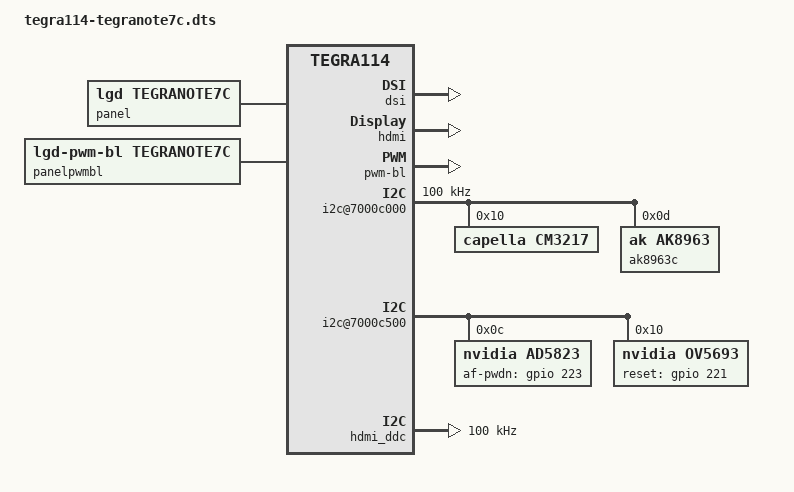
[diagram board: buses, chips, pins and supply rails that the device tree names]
/*
 * Copyright (c) 2013-2014, NVIDIA CORPORATION.  All rights reserved.
 *
 * This program is free software; you can redistribute it and/or modify it
 * under the terms and conditions of the GNU General Public License,
 * version 2, as published by the Free Software Foundation.
 *
 * This program is distributed in the hope it will be useful, but WITHOUT
 * ANY WARRANTY; without even the implied warranty of MERCHANTABILITY or
 * FITNESS FOR A PARTICULAR PURPOSE.  See the GNU General Public License for
 * more details.
 *
 * You should have received a copy of the GNU General Public License
 * along with this program.  If not, see <http://www.gnu.org/licenses/>.
 */

/dts-v1/;

/include/ "tegra114-tegranote7c-common.dtsi"

/ {
	host1x {
		/* tegradc.0 */
		dc@54200000 {
			status = "okay";
			nvidia,dc-flags = "dc_flag_en";
			nvidia,emc-clk-rate = <204000000>;
			nvidia,cmu-enable = <0>;
			dc-default-out {
				nvidia,out-type = "dsi";
				nvidia,out-width = <94>;
				nvidia,out-height = <150>;
				nvidia,out-flags = "continuous_initialized";
				nvidia,out-parent-clk = "pll_d_out0";
			};
			display-timings {
				800x1200-32 {
					clock-frequency = <70666000>;
					hactive = <800>;
					vactive = <1280>;
					hfront-porch = <32>;
					hback-porch = <57>;
					hsync-len = <1>;
					vfront-porch = <28>;
					vback-porch = <14>;
					vsync-len = <1>;
					nvidia,h-ref-to-sync = <10>;
					nvidia,v-ref-to-sync = <1>;
				};
			};
			framebuffer-data {
				nvidia,fb-bpp = <32>; /* bits per pixel */
				nvidia,fb-flags = "flip_on_probe";
				nvidia,fb-xres = <800>;
				nvidia,fb-yres = <1280>;
			};
			smartdimmer {
				status = "disabled";
				nvidia,use-auto-pwm = <0>;
				nvidia,hw-update-delay = <0>;
				nvidia,bin-width = "-1";
				nvidia,aggressiveness = <5>;
				nvidia,use-vid-luma = <0>;
				nvidia,phase-in-settings = <0>;
				nvidia,phase-in-adjustments = <0>;
				nvidia,k-limit-enable = <1>;
				nvidia,k-limit = <200>;
				nvidia,sd-window-enable = <0>;
				nvidia,soft-clipping-enable= <1>;
				nvidia,soft-clipping-threshold = <128>;
				nvidia,smooth-k-enable = <1>;
				nvidia,smooth-k-incr = <4>;
				nvidia,coeff = <5 9 2>;
				nvidia,fc = <0 0>;
				nvidia,blp = <1024 255>;
				nvidia,bltf = <57 65 73 82
						  92 103 114 125
						  138 150 164 178
						  193 208 224 241>;
				nvidia,lut = <255 255 255
						 199 199 199
						 153 153 153
						 116 116 116
						 85 85 85
						 59 59 59
						 36 36 36
						 17 17 17
						 0 0 0>;
				nvidia,use-vpulse2 = <1>;
				nvidia,bl-device-name = "pwm-backlight";
			};
			cmu {
				nvidia,cmu-csc = < 0x106 0x3EB 0x00E
						   0x3F8 0x11B 0x3EB
						   0x003 0x001 0x0FB >;
				nvidia,cmu-lut2 = < 0 2 4 7 9 11 13 14
						    16 17 19 20 21 22 23 24
						    25 26 27 27 28 28 29 29
						    29 30 30 30 30 31 31 31
						    31 31 31 31 31 32 32 32
						    32 32 32 33 33 33 33 33
						    34 34 34 34 35 35 35 35
						    36 36 36 37 37 37 38 38
						    38 39 39 39 40 40 40 41
						    41 41 42 42 42 43 43 44
						    44 44 45 45 45 46 46 46
						    47 47 47 48 48 48 49 49
						    49 49 50 50 50 51 51 51
						    51 52 52 52 52 53 53 53
						    53 54 54 54 54 54 55 55
						    55 55 55 56 56 56 56 56
						    57 57 57 57 57 57 58 58
						    58 58 58 58 59 59 59 59
						    59 59 59 60 60 60 60 60
						    60 60 60 61 61 61 61 61
						    61 61 61 62 62 62 62 62
						    62 62 62 63 63 63 63 63
						    63 63 63 63 64 64 64 64
						    64 64 64 64 65 65 65 65
						    65 65 65 65 66 66 66 66
						    66 66 66 66 67 67 67 67
						    67 67 67 67 68 68 68 68
						    68 68 68 68 69 69 69 69
						    69 69 69 69 70 70 70 70
						    70 70 70 71 71 71 71 71
						    71 71 71 72 72 72 72 72
						    72 72 72 73 73 73 73 73
						    73 73 74 74 74 74 74 74
						    74 74 75 75 75 75 75 75
						    75 75 76 76 76 76 76 76
						    76 76 77 77 77 77 77 77
						    77 77 78 78 78 78 78 78
						    78 78 79 79 79 79 79 79
						    79 79 80 80 80 80 80 80
						    80 80 80 81 81 81 81 81
						    81 81 81 82 82 82 82 82
						    82 82 82 82 83 83 83 83
						    83 83 83 83 83 83 84 84
						    84 84 84 84 84 84 84 85
						    85 85 85 85 85 85 85 85
						    85 86 86 86 86 86 86 86
						    86 86 86 87 87 87 87 87
						    87 87 87 87 87 87 88 88
						    88 88 88 88 88 88 88 88
						    89 89 89 89 89 89 89 89
						    89 89 89 90 90 90 90 90
						    90 90 90 90 90 90 91 91
						    91 91 91 91 91 91 91 91
						    91 91 92 92 92 92 92 92
						    92 92 92 92 92 92 93 93
						    93 93 93 93 93 93 93 93
						    93 94 94 94 94 94 94 94
						    94 94 94 94 94 95 95 95
						    95 95 95 95 95 95 95 95
						    95 95 96 96 96 96 96 96
						    96 96 96 96 96 96 97 97
						    97 97 97 97 97 97 97 97
						    97 97 98 98 98 98 98 98
						    98 98 98 98 98 98 98 99
						    99 100 100 101 102 102 103 104
						   104 105 105 106 107 107 108 108
						   109 110 110 111 111 112 112 113
						   114 114 115 115 116 116 117 117
						   118 118 119 119 120 120 121 121
						   122 122 123 123 124 124 125 125
						   126 126 127 127 128 128 129 129
						   130 130 131 131 132 132 133 133
						   134 134 134 135 135 136 136 137
						   137 138 138 139 139 139 140 140
						   141 141 142 142 142 143 143 144
						   144 144 145 145 146 146 146 147
						   147 148 148 148 149 149 150 150
						   150 151 151 151 152 152 153 153
						   153 154 154 154 155 155 156 156
						   156 157 157 157 158 158 159 159
						   159 160 160 160 161 161 162 162
						   162 163 163 164 164 164 165 165
						   166 166 166 167 167 168 168 168
						   169 169 170 170 170 171 171 172
						   172 172 173 173 174 174 174 175
						   175 176 176 176 177 177 178 178
						   178 179 179 179 180 180 181 181
						   181 182 182 182 183 183 183 184
						   184 185 185 185 186 186 186 187
						   187 187 188 188 189 189 189 190
						   190 190 191 191 191 192 192 192
						   193 193 193 194 194 195 195 195
						   196 196 196 197 197 197 198 198
						   198 199 199 199 200 200 200 201
						   201 201 202 202 202 203 203 203
						   204 204 204 205 205 205 206 206
						   206 207 207 207 208 208 208 209
						   209 209 210 210 210 211 211 211
						   211 212 212 212 213 213 213 214
						   214 214 214 215 215 215 216 216
						   216 216 217 217 217 218 218 218
						   218 219 219 219 220 220 220 220
						   221 221 221 222 222 222 222 223
						   223 223 223 224 224 224 225 225
						   225 225 226 226 226 226 227 227
						   227 227 228 228 228 228 229 229
						   229 229 230 230 230 230 231 231
						   231 231 232 232 232 232 233 233
						   233 233 234 234 234 234 235 235
						   235 235 236 236 236 236 237 237
						   237 237 238 238 238 238 239 239
						   239 239 240 240 240 240 241 241
						   241 241 241 242 242 242 242 243
						   243 243 243 244 244 244 244 245
						   245 245 245 245 246 246 246 246
						   247 247 247 247 248 248 248 248
						   249 249 249 249 249 250 250 250
						   250 251 251 251 251 251 252 252
						   252 252 253 253 253 253 253 254
						   254 254 254 255 255 255 255 255 >;
			};
		};

		/* tegradc.1 */
		dc@54240000 {
			status = "okay";
			nvidia,emc-clk-rate = <300000000>;
			nvidia,cmu-enable = <1>;
			dc-default-out {
				nvidia,out-type = "hdmi";
				nvidia,out-flags = "hotplug_high";
				nvidia,out-parent-clk = "pll_d2_out0";
				nvidia,out-max-pixclk = <148500>;
				nvidia,out-align = "msb";
				nvidia,out-order = "rtob"; /*red to blue*/
				nvidia,out-tmds-cfg {
					tmds-cfg@0 {
						pclk = <27000000>;
						pll0 = <0x01003010>;
						pll1 = <0x00301b00>;
						pe-current = <0x00000000>;
						drive-current = <0x23232323>;
						peak-current = <0x00000000>;
					};
					tmds-cfg@1 {
						pclk = <74250000>;
						pll0 = <0x01003110>;
						pll1 = <0x00301b00>;
						pe-current = <0x00000000>;
						drive-current = <0x21212121>;
						peak-current = <0x03030303>;
					};
					tmds-cfg@2 {
						pclk = <148500000>;
						pll0 = <0x01003310>;
						pll1 = <0x00301b00>;
						pe-current = <0x00000000>;
						drive-current = <0x24242424>;
						peak-current = <0x03030303>;
					};
					tmds-cfg@3 {
						pclk = <0x7fffffff>;
						pll0 = <0x01003f10>;
						pll1 = <0x13300b00>;
						pe-current = <0x00000000>;
						drive-current = <0x24242424>;
						peak-current = <0x07070707>;
					};
				};
			};
			framebuffer-data {
				nvidia,fb-bpp = <32>; /* bits per pixel */
				nvidia,fb-flags = "flip_on_probe";
				nvidia,fb-xres = <1024>;
				nvidia,fb-yres = <600>;
			};
		};
		dsi {
			status = "okay";
			nvidia,panel = <&panel>;
			nvidia,dsi-n-data-lanes = <4>;
			nvidia,dsi-video-burst-mode = "none_burst";
			nvidia,dsi-pixel-format = "24_p";
			nvidia,dsi-ref-rate = <60>;
			nvidia,dsi-virtual-ch = "vc0";
			nvidia,dsi-instance = <0>; /* 0 or 1 */
			nvidia,dsi-panel-reset = <0>;
			nvidia,dsi-power-saving-suspend = <1>;
			nvidia,dsi-video-data-type = "video";
			nvidia,dsi-video-clk-mode = "txonly";
			nvidia,dsi-phy-datzero = <270>;
			nvidia,dsi-phy-hsprepare = <30>;
			nvidia,dsi-phy-clkzero = <330>;
			nvidia,dsi-phy-clkprepare = <27>;
		};
		hdmi {
			status = "okay";
			nvidia,regulators = "avdd_hdmi",
					    "avdd_hdmi_pll",
					    "vdd_hdmi_5v0";
			nvidia,ddc-i2c-bus = <&hdmi_ddc>;
			nvidia,hpd-gpio = <&gpio 111 1>;
			nvidia,hotplug-report = <1>;
		};
	};
	pwm-bl {
		status = "okay";
		nvidia,panel-pwm-bl = <&panelpwmbl>;
		nvidia,pwm-id = <1>;
		nvidia,max-brightness = <255>;
		nvidia,dft-brightness = <153>;
		nvidia,dft-charge-brightness = <60>;
		nvidia,pwm-period-ns = <1000000>;
		nvidia,disable-edp-throttle = <1>;
		nvidia,edp-states = <1711 1390 1057 713 360 0>;
		nvidia,edp-brightness = <255 204 153 101 50 0>;
		nvidia,pwm-gpio = <&gpio 57 0>; /* gpio PH1 */
	};

	panel: panel {
		compatible = "lgd,tegranote7c";
		status = "okay";
		nvidia,regulators = "avdd_lcd",
				    "vdd_lcd_bl_en",
				    "dvdd_lcd";
	};

	panelpwmbl: panelpwmbl {
		compatible = "lgd-pwm-bl,tegranote7c";
		status = "okay";
		nvidia,bl-output = < 0 1 2 3 4 6 7 8 9 10
				     11 12 13 14 15 16 16 17 18 19
				     20 21 22 23 24 25 25 26 27 28
				     29 30 31 32 33 34 35 36 37 38
				     39 40 41 42 43 44 45 46 47 48
				     49 50 51 52 53 54 55 56 57 58
				     59 60 61 62 63 64 65 66 67 68
				     69 70 71 72 73 74 74 75 76 77
				     78 79 80 81 82 83 84 85 86 87
				     88 89 90 91 92 93 94 95 96 97
				     98 99 100 101 102 103 104 105 106 107
				     108 109 110 111 112 113 114 115 116 117
				     118 119 120 121 122 123 124 125 126 127
				     128 129 130 131 132 133 134 135 136 137
				     138 139 140 141 142 143 144 145 146 147
				     148 149 150 151 152 153 154 155 156 157
				     158 159 160 161 162 164 165 166 167 168
				     169 170 171 172 173 174 175 176 177 178
				     179 180 181 182 183 184 185 186 187 188
				     189 190 191 192 193 194 195 196 197 198
				     199 200 201 202 203 205 206 207 208 209
				     210 211 212 213 214 215 216 217 218 219
				     220 221 222 223 224 225 226 227 228 229
				     230 231 232 233 234 236 237 238 239 240
				     241 242 243 244 245 246 247 248 249 250
				     251 252 253 253 254 255 >;
	};

	/* GEN1 */
	i2c@7000c000 {
		status = "okay";
		clock-frequency = <100000>;

		/* ALS sensor */
		cm3217@10 {
			compatible = "capella,cm3217";
			reg = <0x10>;
			levels = <10 160 225 320 640 1280 2600 5800 8000 10240>;
			golden_adc = <0>;
		};

		/* Compass sensor */
		ak8963c@0d {
			compatible = "ak,ak8963";
			reg = <0x0d>;
			orientation = [ff 00 00 00 01 00 00 00 ff];
			config = "mpu";
			sec-slave-id = <18>;
		};
	};

	/* CAM */
	i2c@7000c500 {
		status = "okay";
		ad5823@0c {
			compatible = "nvidia,ad5823";
			reg = <0x0c>;
			af-pwdn-gpios = <&gpio 223 0>; /* gpio PBB7 */
		};
		ov5693@10 {
			compatible = "nvidia,ov5693";
			reg = <0x10>;
			nvidia,num = <5693>;
			nvidia,dev-name = "camera";
			nvidia,use-vcm-vdd;
			reset-gpios = <&gpio 221 0>; /* gpio PBB5 */
		};
	};
	/* DDC */
	hdmi_ddc: i2c@7000c700 {
		status = "okay";
		clock-frequency = <100000>;
	};

	pwfm@0x7000a010 {
		status = "okay";
	};
};
